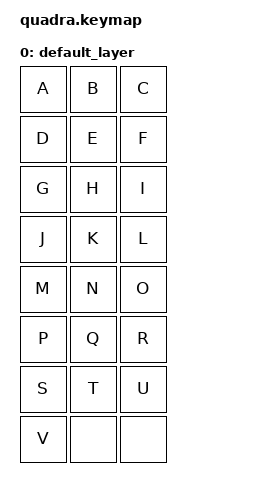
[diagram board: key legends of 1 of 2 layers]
#include <behaviors.dtsi>
#include <dt-bindings/zmk/keys.h>
#include <dt-bindings/zmk/rgb.h>

    / {
    chosen {
        zmk,kscan = &kscan0;
        /* zmk,matrix-transform = &default_transform; */ /* ←これを削除またはコメントアウト */
    };
    
    keymap {
        compatible = "zmk,keymap";

        /*
         * レイヤー 0: デフォルト (右手キーマップ)
         * キー数: 22 (5 + 5 + 6 + 6)
         * トランスフォームの記述順 (SWxxx) に正確に対応させる必要があります。
         */
        default_layer {
            bindings = <
                /* ---------------------------------------------------------
                kscan_a (順方向：上側ボタン群 12マス)
                ROW0〜ROW3  ×  COL0〜COL2
                --------------------------------------------------------- */
                &kp A  &kp B  &kp C  /* ROW0 (D3ピン) × COL0, 1, 2 */
                &kp D  &kp E  &kp F  /* ROW1 (D2ピン) × COL0, 1, 2 */
                &kp G  &kp H  &kp I  /* ROW2 (D1ピン) × COL0, 1, 2 */
                &kp J  &kp K  &kp L  /* ROW3 (D0ピン) × COL0, 1, 2 */

                /* ---------------------------------------------------------
                kscan_b (逆方向：下側ボタン群 12マス)
                ROW4〜ROW7  ×  COL0〜COL2
                --------------------------------------------------------- */
                &kp M  &kp N  &kp O  /* ROW4 (実際はCOL0から駆動) × ROW0, 1, 2 */
                &kp P  &kp Q  &kp R  /* ROW5 (実際はCOL1から駆動) × ROW0, 1, 2 */
                &kp S  &kp T  &kp U  /* ROW6 (実際はCOL2から駆動) × ROW0, 1, 2 */
                &kp V  &none  &none  /* ROW7 (回路無し空きエリア) */
                >;
        };

        /*
         * レイヤー 1: LEDコントロール & 設定
         */
        lower_layer {
            bindings = <
                /* ROW 0: RGBトグル, RGBエフェクト切替, 輝度アップ, 輝度ダウン, なし */
                &rgb_ug RGB_TOG &rgb_ug RGB_EFF &rgb_ug RGB_BRI &rgb_ug RGB_BRD &none
                /* ROW 1 */
                &none           &none           &none           &none           &none
                /* ROW 2 */
                &none           &none           &none           &none           &none     &none
                /* ROW 3 */
                &trans          &none           &none           &none           &none     &none
            >;
        };
    };
};
